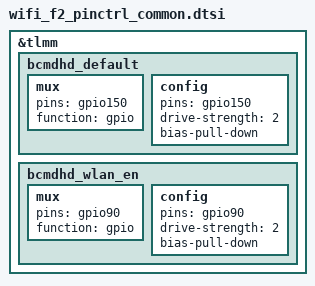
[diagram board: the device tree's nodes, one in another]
/* Copyright (c) 2019, The Linux Foundation. All rights reserved.
 *
 * This program is free software; you can redistribute it and/or modify
 * it under the terms of the GNU General Public License version 2 and
 * only version 2 as published by the Free Software Foundation.
 *
 * This program is distributed in the hope that it will be useful,
 * but WITHOUT ANY WARRANTY; without even the implied warranty of
 * MERCHANTABILITY or FITNESS FOR A PARTICULAR PURPOSE.  See the
 * GNU General Public License for more details.
 */

&tlmm {
	bcmdhd_default: bcmdhd_default {
		mux {
			pins = "gpio150";
			function = "gpio";
		};
		config {
			pins = "gpio150";
			drive-strength = <2>;   /* 2 mA */
			bias-pull-down;         /* PULL DOWN */
		};
	};

	bcmdhd_wlan_en: bcmdhd_wlan_en {
		mux {
			pins = "gpio90";
			function = "gpio";
		};
		config {
			pins = "gpio90";
			drive-strength = <2>;   /* 2 mA */
			bias-pull-down;         /* PULL DOWN */
		};
	};
};
